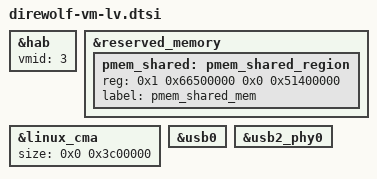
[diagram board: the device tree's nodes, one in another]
&hab {
	vmid = <3>;
};

&reserved_memory {
	pmem_shared: pmem_shared_region {
		reg = <0x1 0x66500000 0x0 0x51400000>;
		label = "pmem_shared_mem";
	};
};

&linux_cma {
	size = <0x0 0x3c00000>;
};

#include "display/quin-vm-display-lxc.dtsi"
#include "direwolf-vm-lv-cnss.dtsi"

&usb0 {
	status = "okay";
};

&usb2_phy0 {
	status = "okay";
};
